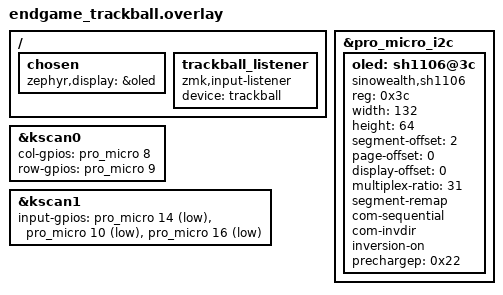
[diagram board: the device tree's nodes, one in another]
#include "endgame.dtsi"
#include <dt-bindings/zmk/matrix_transform.h>

&pro_micro_i2c {
    status = "okay";

    oled: sh1106@3c {
        compatible = "sinowealth,sh1106";
        reg = <0x3c>;
        width = <132>;
        height = <64>;
        segment-offset = <2>;
        page-offset = <0>;
        display-offset = <0>;
        multiplex-ratio = <31>;
        segment-remap;
	    com-sequential;
	    com-invdir;
        inversion-on;
        prechargep = <0x22>;
    };
};

/ {
    chosen {
        zephyr,display = &oled;
    };

    trackball_listener {
        compatible = "zmk,input-listener";
        device = <&trackball>;
	};

};

&kscan0 {
    col-gpios
        = <&pro_micro 8 GPIO_ACTIVE_HIGH>
        ;
    row-gpios
        = <&pro_micro 9 (GPIO_ACTIVE_HIGH | GPIO_PULL_DOWN)>
        ;
};

&kscan1 {
	input-gpios
		= <&pro_micro 14 (GPIO_ACTIVE_LOW | GPIO_PULL_UP)>
		, <&pro_micro 10 (GPIO_ACTIVE_LOW | GPIO_PULL_UP)>
		, <&pro_micro 16 (GPIO_ACTIVE_LOW | GPIO_PULL_UP)>
        ;
};
